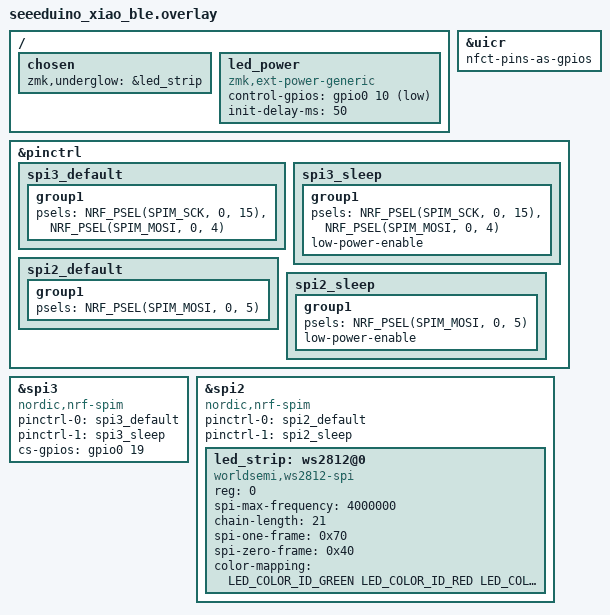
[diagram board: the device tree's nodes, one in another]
/*
 * Copyright (c) 2026 The ZMK Contributors
 *
 * SPDX-License-Identifier: MIT
 *
 * nice!view bus for the XIAO nRF52840 Plus / Sense Plus. All three lines sit
 * on pins rated for a fast clock (docs/PINOUT.md). SCK and CS use the Plus-only
 * pads D11 and D12, which the xiao_d connector does not map, so they are
 * given as raw ports.
 *
 * SPIM3 rather than SPIM0: SPIM0 shares its peripheral with TWIM0, the bus
 * the Sense's on-module IMU uses, so this leaves the IMU free to enable later.
 *
 * Rev. 3 RGB: 21 WS2812B-2020 LEDs, one under each PG1316S key, chained from
 * D5 (P0.05, a fast pin) through SPIM2. Their 3V3 feed is switched by a PMOS
 * whose gate is D15 (P0.10, active low), driven by ZMK ext-power so the LEDs
 * draw nothing when lighting is off. COL5 moved from D5 to D14 (P0.09).
 * P0.09/P0.10 are NFC pads by default; uicr releases them as GPIOs.
 */

#include <dt-bindings/led/led.h>

&uicr {
    nfct-pins-as-gpios;
};

&pinctrl {
    spi3_default: spi3_default {
        group1 {
            psels = <NRF_PSEL(SPIM_SCK, 0, 15)>,  /* D11 */
                    <NRF_PSEL(SPIM_MOSI, 0, 4)>;  /* D4 */
        };
    };

    spi3_sleep: spi3_sleep {
        group1 {
            psels = <NRF_PSEL(SPIM_SCK, 0, 15)>,
                    <NRF_PSEL(SPIM_MOSI, 0, 4)>;
            low-power-enable;
        };
    };

    spi2_default: spi2_default {
        group1 {
            psels = <NRF_PSEL(SPIM_MOSI, 0, 5)>;  /* D5: LED data */
        };
    };

    spi2_sleep: spi2_sleep {
        group1 {
            psels = <NRF_PSEL(SPIM_MOSI, 0, 5)>;
            low-power-enable;
        };
    };
};

nice_view_spi: &spi3 {
    compatible = "nordic,nrf-spim";
    pinctrl-0 = <&spi3_default>;
    pinctrl-1 = <&spi3_sleep>;
    pinctrl-names = "default", "sleep";
    cs-gpios = <&gpio0 19 GPIO_ACTIVE_HIGH>;  /* D12; the LS0xx chip select is active high */
};

&spi2 {
    compatible = "nordic,nrf-spim";
    status = "okay";
    pinctrl-0 = <&spi2_default>;
    pinctrl-1 = <&spi2_sleep>;
    pinctrl-names = "default", "sleep";

    led_strip: ws2812@0 {
        compatible = "worldsemi,ws2812-spi";
        reg = <0>;
        spi-max-frequency = <4000000>;
        chain-length = <21>;
        spi-one-frame = <0x70>;
        spi-zero-frame = <0x40>;
        color-mapping = <LED_COLOR_ID_GREEN LED_COLOR_ID_RED LED_COLOR_ID_BLUE>;
    };
};

/ {
    chosen {
        zmk,underglow = &led_strip;
    };

    /* PMOS gate on D15: low = LEDs powered */
    led_power: led_power {
        compatible = "zmk,ext-power-generic";
        control-gpios = <&gpio0 10 GPIO_ACTIVE_LOW>;
        init-delay-ms = <50>;
    };
};
